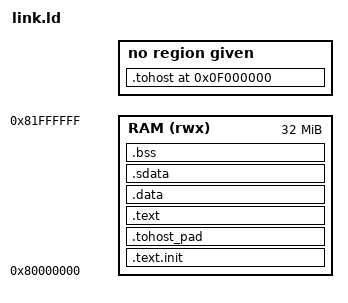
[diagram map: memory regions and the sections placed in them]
/* AUTO-GENERATED by scripts/gen_mem_map.py — DO NOT EDIT */
/* Source: design/common/mem_map.json (profile: riscof) */
OUTPUT_ARCH( "riscv" )
ENTRY(rvtest_entry_point)

MEMORY
{
  RAM (rwx) : ORIGIN = 0x80000000, LENGTH = 0x02000000
}

SECTIONS
{
  .text.init : { *(.text.init) } > RAM

  /* Reserve a NOBITS 1-page slot to match spike's layout. spike's
     reference linker puts a real .tohost section in RAM between
     .text.init and .data, so .data lands at .text.init_end + 2 pages.
     ntiny puts .tohost at a fixed bus-monitored address outside RAM,
     so it doesn't need a backing slot — but if we don't reserve one,
     .data ends up at .text.init_end + 1 page, shifted DOWN by 0x1000
     relative to spike's binary. Tests that use absolute PC values
     (AUIPC + signature writes of EPCs) then diverge from the spike
     reference signature, causing dozens of false-positive RISCOF
     failures across the PMP / vm_sv32 / privilege suites. */
  . = ALIGN(0x1000);
  .tohost_pad (NOLOAD) : { . = . + 0x1000; } > RAM

  . = ALIGN(0x1000);
  .text : { *(.text) } > RAM

  . = ALIGN(0x1000);
  .data : { *(.data) *(.data.*) *(.data.string) } > RAM
  .sdata : { *(.sdata) *(.sdata.*) } > RAM
  .bss (NOLOAD) : { *(.bss) *(.bss.*) } > RAM

  /* tohost at fixed bus address — no backing memory needed, testbench monitors bus writes */
  .tohost 0x0F000000 (NOLOAD) : { *(.tohost) }

  _end = .;
}
